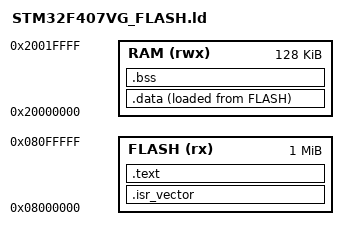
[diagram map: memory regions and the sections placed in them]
/**
 * STM32F407VG: Flash 1MiB @0x08000000, 연속 SRAM 128KiB @0x20000000 (요약 맵)
 * CCM(0x10000000) 미사용 — 제품 링크 시 메모리 맵에 맞게 조정하십시오.
 */
_estack = ORIGIN(RAM) + LENGTH(RAM);

MEMORY
{
    FLASH (rx)  : ORIGIN = 0x08000000, LENGTH = 1024K
    RAM (rwx)   : ORIGIN = 0x20000000, LENGTH = 128K
}

ENTRY(Reset_Handler)

SECTIONS
{
    .isr_vector : ALIGN(4)
    {
        KEEP(*(.isr_vector))
    } > FLASH

    .text : ALIGN(4)
    {
        *(.text*)
        *(.rodata*)
        KEEP(*(.init))
        KEEP(*(.fini))
        . = ALIGN(4);
        _etext = .;
    } > FLASH

    _sidata = LOADADDR(.data);

    .data : ALIGN(4)
    {
        _sdata = .;
        *(.data*)
        . = ALIGN(4);
        _edata = .;
    } > RAM AT > FLASH

    .bss (NOLOAD) : ALIGN(4)
    {
        _sbss = .;
        *(.bss*)
        *(COMMON)
        . = ALIGN(4);
        _ebss = .;
    } > RAM

    /DISCARD/ :
    {
        *(.ARM.exidx*)
        *(.ARM.extab*)
    }
}
